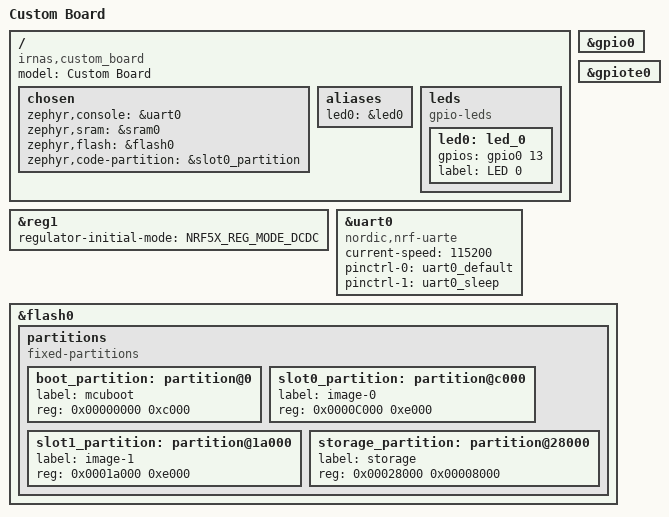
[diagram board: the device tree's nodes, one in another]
/*
 * Copyright (c) 2021 Nordic Semiconductor ASA
 * SPDX-License-Identifier: Apache-2.0
 */

/dts-v1/;
#include <nordic/nrf52840_qiaa.dtsi>
#include "custom_board-pinctrl.dtsi"

/ {
	model = "Custom Board";
	compatible = "irnas,custom_board";

	chosen {
		zephyr,console = &uart0;
		zephyr,sram = &sram0;
		zephyr,flash = &flash0;
		zephyr,code-partition = &slot0_partition;
	};
	aliases {
		led0 = &led0;
	};

	leds {
		compatible = "gpio-leds";
		led0: led_0 {
			gpios = <&gpio0 13 GPIO_ACTIVE_HIGH>;
			label = "LED 0";
		};
	};
};

&reg1 {
	regulator-initial-mode = <NRF5X_REG_MODE_DCDC>;
};

&gpio0 {
	status = "okay";
};

&gpiote0 {
	status = "okay";
};


&uart0 {
	compatible = "nordic,nrf-uarte";
	status = "okay";
	current-speed = <115200>;
	pinctrl-0 = <&uart0_default>;
	pinctrl-1 = <&uart0_sleep>;
	pinctrl-names = "default", "sleep";
};

&flash0 {
	partitions {
		compatible = "fixed-partitions";
		#address-cells = <1>;
		#size-cells = <1>;

		boot_partition: partition@0 {
			label = "mcuboot";
			reg = <0x00000000 0xc000>;
		};
		slot0_partition: partition@c000 {
			label = "image-0";
			reg = <0x0000C000 0xe000>;
		};
		slot1_partition: partition@1a000 {
			label = "image-1";
			reg = <0x0001a000 0xe000>;
		};
		storage_partition: partition@28000 {
			label = "storage";
			reg = <0x00028000 0x00008000>;
		};
	};
};
